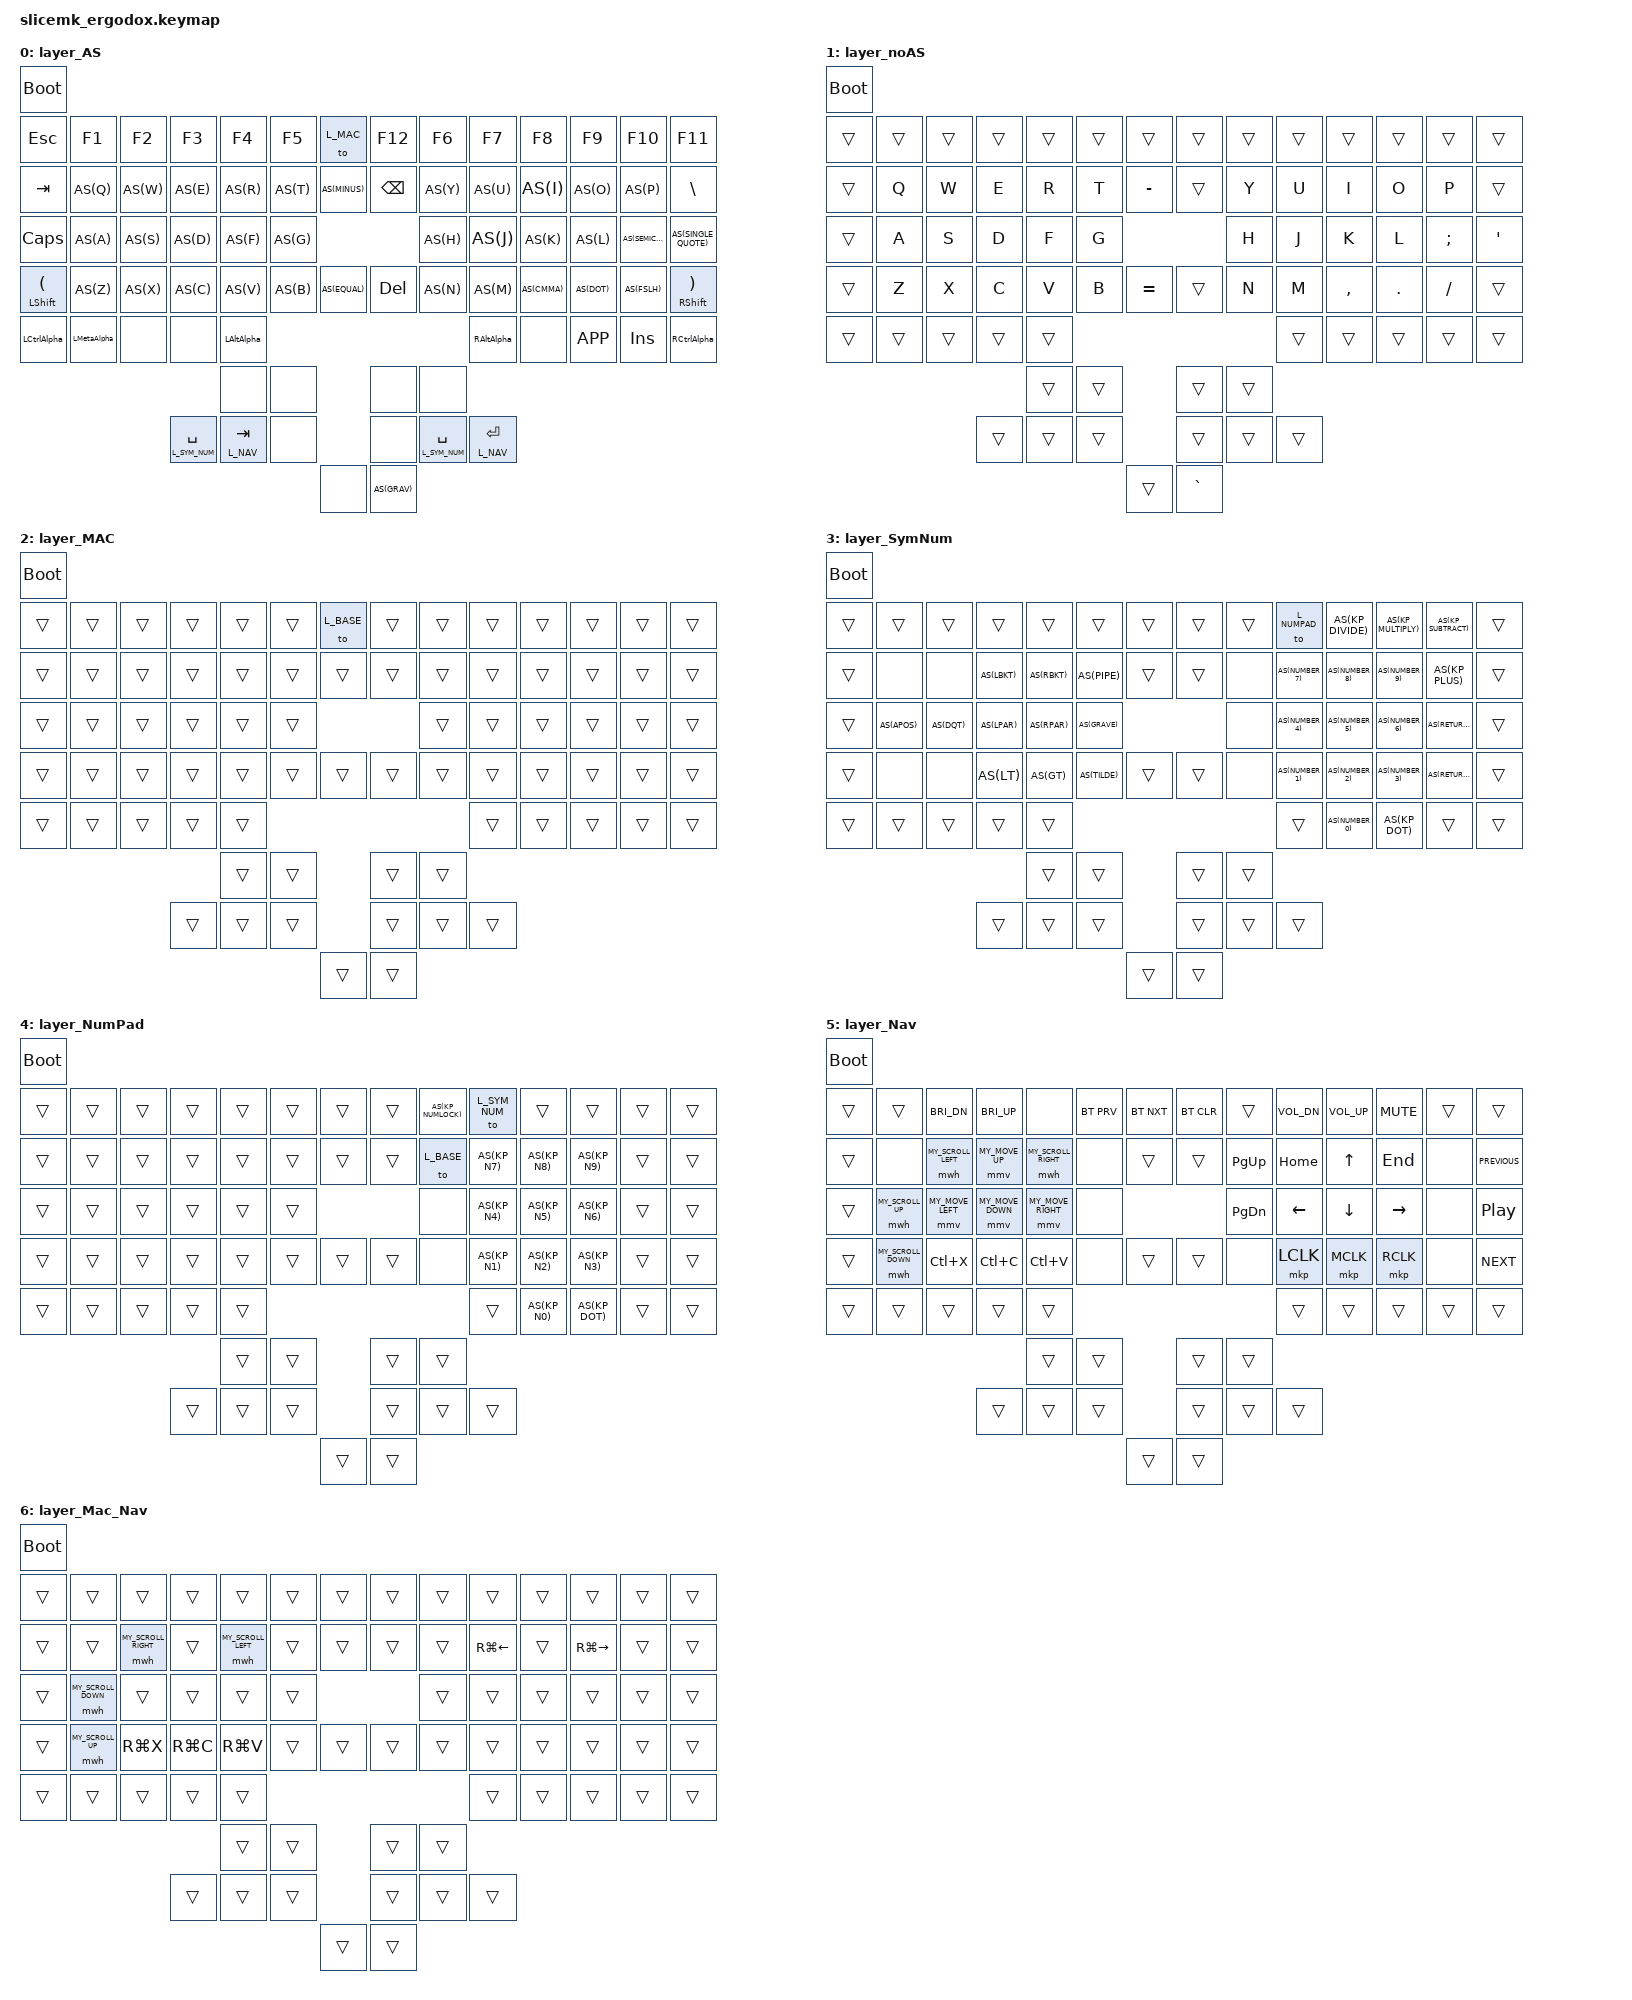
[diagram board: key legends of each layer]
#include <behaviors.dtsi>
#include <dt-bindings/zmk/bt.h>
#include <dt-bindings/zmk/keys.h>
#include <dt-bindings/zmk/outputs.h>
#include <dt-bindings/zmk/mouse.h>

// layers
#define L_BASE 0
#define L_NOAS 1
#define L_MAC 2
#define L_SYM_NUM 3
#define L_NUMPAD 4
#define L_NAV 5
#define L_MAC_NAV 6

// Mouse helpers
#define MY_MOUSE_SPEED 1400 // must be less than 16 bit signed (-32,768 to 32,767). Default 600
#define MY_MOVE_UP MOVE_VERT(-MY_MOUSE_SPEED)
#define MY_MOVE_DOWN MOVE_VERT(MY_MOUSE_SPEED)
#define MY_MOVE_LEFT MOVE_HOR(-MY_MOUSE_SPEED)
#define MY_MOVE_RIGHT MOVE_HOR(MY_MOUSE_SPEED)


#define MOUSE_LCLK &mkp LCLK
#define MOUSE_MCLK &mkp MCLK
#define MOUSE_RCLK &mkp RCLK
#define M_UP &mmv MY_MOVE_UP
#define M_DOWN &mmv MY_MOVE_DOWN
#define M_LEFT &mmv MY_MOVE_LEFT
#define M_RIGHT &mmv MY_MOVE_RIGHT

#define MY_SCROLL_SPEED 10 // must be less than 8 bit signed (	-128 to 127). Default 10
#define MY_SCROLL_UP SCROLL_VERT(MY_SCROLL_SPEED)
#define MY_SCROLL_DOWN SCROLL_VERT(-MY_SCROLL_SPEED)
#define MY_SCROLL_LEFT SCROLL_HOR(-MY_SCROLL_SPEED)
#define MY_SCROLL_RIGHT SCROLL_HOR(MY_SCROLL_SPEED)
#define M_WHEEL_L &mwh MY_SCROLL_LEFT
#define M_WHEEL_R &mwh MY_SCROLL_RIGHT
#define M_WHEEL_U &mwh MY_SCROLL_UP
#define M_WHEEL_D &mwh MY_SCROLL_DOWN

// Mouse movement settings
&mmv {
	delay-ms = <0>; // <0> default
	time-to-max-speed-ms = <300>; // <300> default
	acceleration-exponent = <1>; // <1> default
};

// Mouse Wheel settings
&mwh {
	delay-ms = <0>; // <0> default
	time-to-max-speed-ms = <0>; // <300> dafault
	acceleration-exponent = <0>; // <0> default
};

// Auto shift helper
#define AS(keycode) &as LS(keycode) keycode

// Windows helpers
#define W_CUT &kp LC(X)
#define W_COPY &kp LC(C)
#define W_PASTE &kp LC(V)

// Mac Helpers
#define M_LINE_START &kp RG(LEFT_ARROW)
#define M_LINE_END &kp RG(RIGHT_ARROW)
#define M_CUT &kp RG(X)
#define M_COPY &kp RG(C)
#define M_PASTE &kp RG(V)

/ { // root
	macros {
		LCtrlAlpha:LCtrlAlpha {
			compatible = "zmk,behavior-macro";
			label = "pressLeftCtrlNoAutoShiftMacro";
			#binding-cells = <0>;
			wait-ms = <0>;
			tap-ms = <0>;
			bindings
			= <&macro_press &mo L_NOAS &kp LCTRL>,
				<&macro_pause_for_release>,
				<&macro_release &mo L_NOAS &kp LCTRL> ;
		};
		LMetaAlpha:LMetaAlpha {
			compatible = "zmk,behavior-macro";
			label = "pressLeftMetaNoAutoShiftMacro";
			#binding-cells = <0>;
			wait-ms = <0>;
			tap-ms = <0>;
			bindings
			= <&macro_press &mo L_NOAS &kp LEFT_META>,
				<&macro_pause_for_release>,
				<&macro_release &mo L_NOAS &kp LEFT_META> ;
		};
		LAltAlpha:LAltAlpha {
			compatible = "zmk,behavior-macro";
			label = "pressLeftAltNoAutoShiftMacro";
			#binding-cells = <0>;
			wait-ms = <0>;
			tap-ms = <0>;
			bindings
			= <&macro_press &mo L_NOAS &kp LALT>,
				<&macro_pause_for_release>,
				<&macro_release &mo L_NOAS &kp LALT> ;
		};
		RCtrlAlpha:RCtrlAlpha {
			compatible = "zmk,behavior-macro";
			label = "pressRightCtrlNoAutoShiftMacro";
			#binding-cells = <0>;
			wait-ms = <0>;
			tap-ms = <0>;
			bindings
			= <&macro_press &mo L_NOAS &kp RCTRL>,
				<&macro_pause_for_release>,
				<&macro_release &mo L_NOAS &kp RCTRL> ;
		};
		RMetaAlpha:RMetaAlpha {
			compatible = "zmk,behavior-macro";
			label = "pressRightMetaNoAutoShiftMacro";
			#binding-cells = <0>;
			wait-ms = <0>;
			tap-ms = <0>;
			bindings
			= <&macro_press &mo L_NOAS &kp RIGHT_META>,
				<&macro_pause_for_release>,
				<&macro_release &mo L_NOAS &kp RIGHT_META> ;
		};
		RAltAlpha:RAltAlpha {
			compatible = "zmk,behavior-macro";
			label = "pressRightAltNoAutoShiftMacro";
			#binding-cells = <0>;
			wait-ms = <0>;
			tap-ms = <0>;
			bindings
			= <&macro_press &mo L_NOAS &kp RALT>,
				<&macro_pause_for_release>,
				<&macro_release &mo L_NOAS &kp RALT> ;
		};
	}; // macros

	behaviors {
		as: auto_shift {
			compatible = "zmk,behavior-hold-tap";
			label = "AUTO_SHIFT";
			#binding-cells = <2>;
			tapping_term_ms = <260>; // 300->slow, 190->fast
			quick_tap_ms = <0>;
			flavor = "tap-preferred";
			bindings = <&kp>, <&kp>;
		};
	}; // behaviors

	conditional_layers {
		compatible = "zmk,conditional-layers";
		tri_layer {
				if-layers = <L_MAC L_NAV>;
				then-layer = <L_MAC_NAV>;
		};
	}; // conditional_layers

	keymap {
		compatible = "zmk,keymap";
		layer_AS {  // L_BASE
			bindings = <
				&bootloader
				&kp ESC             &kp F1       &kp F2       &kp F3       &kp F4       &kp F5  &to L_MAC       &kp F12    &kp F6       &kp F7       &kp F8       &kp F9       &kp F10         &kp F11
				&kp TAB             AS(Q)        AS(W)        AS(E)        AS(R)        AS(T)   AS(MINUS)       &kp BKSP   AS(Y)        AS(U)        AS(I)        AS(O)        AS(P)           &kp BSLH
				&kp CAPS            AS(A)        AS(S)        AS(D)        AS(F)        AS(G)                              AS(H)        AS(J)        AS(K)        AS(L)        AS(SEMICOLON)   AS(SINGLE_QUOTE)
				&mt LSHIFT LPAR     AS(Z)        AS(X)        AS(C)        AS(V)        AS(B)   AS(EQUAL)       &kp DEL    AS(N)        AS(M)        AS(CMMA)     AS(DOT)      AS(FSLH)        &mt RSHIFT RPAR
				&LCtrlAlpha         &LMetaAlpha  &none        &none        &LAltAlpha                                                   &RAltAlpha   &none        &kp K_APP    &kp INS         &RCtrlAlpha
				                                                                 &none          &none           &none    &none
				                                            &lt L_SYM_NUM SPC    &lt L_NAV TAB  &none           &none    &lt L_SYM_NUM SPC    &lt L_NAV RET
				                                                                                &none           AS(GRAV)
			>; // bindings
		}; // layer

		layer_noAS {  // L_XYZ
			bindings = <
				&bootloader
				&trans  &trans  &trans  &trans  &trans  &trans  &trans       &trans  &trans  &trans  &trans   &trans  &trans        &trans
				&trans  &kp Q   &kp W   &kp E   &kp R   &kp T   &kp MINUS    &trans  &kp Y   &kp U   &kp I    &kp O   &kp P         &trans
				&trans  &kp A   &kp S   &kp D   &kp F   &kp G                        &kp H   &kp J   &kp K    &kp L   &kp SEMICOLON &kp SINGLE_QUOTE
				&trans  &kp Z   &kp X   &kp C   &kp V   &kp B   &kp EQUAL    &trans  &kp N   &kp M   &kp CMMA &kp DOT &kp FSLH      &trans
				&trans  &trans  &trans  &trans  &trans                                       &trans  &trans   &trans  &trans        &trans
				                                        &trans  &trans       &trans  &trans
				                                &trans  &trans  &trans       &trans  &trans  &trans
				                                                &trans       &kp GRAV
			>; // bindings
		}; // layer

		layer_MAC {  // L_MAC
			bindings = <
				&bootloader
				&trans  &trans  &trans  &trans  &trans  &trans  &to L_BASE   &trans  &trans  &trans  &trans  &trans  &trans  &trans
				&trans  &trans  &trans  &trans  &trans  &trans  &trans       &trans  &trans  &trans  &trans  &trans  &trans  &trans
				&trans  &trans  &trans  &trans  &trans  &trans                       &trans  &trans  &trans  &trans  &trans  &trans
				&trans  &trans  &trans  &trans  &trans  &trans  &trans       &trans  &trans  &trans  &trans  &trans  &trans  &trans
				&trans  &trans  &trans  &trans  &trans                                       &trans  &trans  &trans  &trans  &trans
				                                       &trans  &trans        &trans  &trans
				                               &trans  &trans  &trans        &trans  &trans  &trans
				                                               &trans        &trans
			>; // bindings
		}; // layer



		layer_SymNum { // L_SYM_NUM
			bindings = <
				&bootloader
				&trans   &trans       &trans       &trans       &trans     &trans    &trans     &trans &trans &to L_NUMPAD AS(KP_DIVIDE)  AS(KP_MULTIPLY)  AS(KP_SUBTRACT)  &trans
				&trans   &none        &none        AS(LBKT)     AS(RBKT)   AS(PIPE)  &trans     &trans &none  AS(NUMBER_7) AS(NUMBER_8)   AS(NUMBER_9)     AS(KP_PLUS)      &trans
				&trans   AS(APOS)     AS(DQT)      AS(LPAR)     AS(RPAR)   AS(GRAVE)                   &none  AS(NUMBER_4) AS(NUMBER_5)   AS(NUMBER_6)     AS(RETURN2)      &trans
				&trans   &none        &none        AS(LT)       AS(GT)     AS(TILDE) &trans     &trans &none  AS(NUMBER_1) AS(NUMBER_2)   AS(NUMBER_3)     AS(RETURN2)      &trans
				&trans   &trans       &trans       &trans       &trans                                        &trans       AS(NUMBER_0)   AS(KP_DOT)       &trans           &trans
				                                                               &trans &trans   &trans  &trans
				                                                       &trans  &trans &trans   &trans  &trans &trans
				                                                                      &trans   &trans
			>; // bindings
		}; // layer

		layer_NumPad {  // L_NUMPAD
			bindings = <
				&bootloader
				&trans   &trans       &trans       &trans       &trans     &trans    &trans     &trans AS(KP_NUMLOCK)  &to L_SYM_NUM  &trans          &trans           &trans      &trans
				&trans   &trans       &trans       &trans       &trans     &trans    &trans     &trans &to L_BASE      AS(KP_N7)      AS(KP_N8)       AS(KP_N9)         &trans      &trans
				&trans   &trans       &trans       &trans       &trans     &trans                      &none           AS(KP_N4)      AS(KP_N5)       AS(KP_N6)         &trans      &trans
				&trans   &trans       &trans       &trans       &trans     &trans    &trans     &trans &none           AS(KP_N1)      AS(KP_N2)       AS(KP_N3)         &trans      &trans
				&trans   &trans       &trans       &trans       &trans                                                 &trans         AS(KP_N0)       AS(KP_DOT)        &trans      &trans
				                                                               &trans &trans   &trans  &trans
				                                                       &trans  &trans &trans   &trans  &trans &trans
				                                                                      &trans   &trans
			>; // bindings
		}; // layer

		layer_Nav { // L_NAV
			bindings = <
				&bootloader
				&trans &trans     &kp C_BRI_DN  &kp C_BRI_UP  &none          &bt BT_PRV &bt BT_NXT      &bt BT_CLR  &trans        &kp C_VOL_DN   &kp C_VOL_UP   &kp C_MUTE      &trans       &trans
				&trans &none      M_WHEEL_L     M_UP          M_WHEEL_R      &none      &trans          &trans      &kp PAGE_UP   &kp HOME       &kp UP_ARROW   &kp END         &none        &kp C_PREVIOUS
				&trans M_WHEEL_U  M_LEFT        M_DOWN        M_RIGHT        &none                                  &kp PAGE_DOWN &kp LEFT_ARROW &kp DOWN_ARROW &kp RIGHT_ARROW &none        &kp C_PLAY_PAUSE
				&trans M_WHEEL_D  W_CUT         W_COPY        W_PASTE        &none      &trans          &trans      &none         MOUSE_LCLK     MOUSE_MCLK     MOUSE_RCLK      &none        &kp C_NEXT
				&trans &trans     &trans        &trans        &trans                                                              &trans         &trans         &trans          &trans       &trans
				                                                                &trans &trans           &trans      &trans
				                                                       &trans   &trans &trans           &trans      &trans   &trans
				                                                                       &trans           &trans
			>; // bindings
		}; // layer

		layer_Mac_Nav { // L_MAC_NAV
			bindings = <
				&bootloader
				&trans  &trans     &trans      &trans  &trans     &trans  &trans       &trans  &trans  &trans       &trans  &trans      &trans  &trans
				&trans  &trans     M_WHEEL_R   &trans  M_WHEEL_L  &trans  &trans       &trans  &trans  M_LINE_START &trans  M_LINE_END  &trans  &trans
				&trans  M_WHEEL_D  &trans      &trans  &trans     &trans                       &trans  &trans       &trans  &trans      &trans  &trans
				&trans  M_WHEEL_U  M_CUT       M_COPY  M_PASTE     &trans  &trans       &trans  &trans  &trans       &trans  &trans      &trans  &trans
				&trans  &trans     &trans      &trans  &trans                                       &trans          &trans  &trans      &trans  &trans
				                                        &trans  &trans       &trans  &trans
				                                &trans  &trans  &trans       &trans  &trans  &trans
				                                                &trans       &trans
			>; // bindings
		}; // layer

		/* transparent starter
		layer_1 {  // L_XYZ
			bindings = <
				&bootloader
				&trans  &trans  &trans  &trans  &trans  &trans  &trans       &trans  &trans  &trans  &trans  &trans  &trans  &trans
				&trans  &trans  &trans  &trans  &trans  &trans  &trans       &trans  &trans  &trans  &trans  &trans  &trans  &trans
				&trans  &trans  &trans  &trans  &trans  &trans                       &trans  &trans  &trans  &trans  &trans  &trans
				&trans  &trans  &trans  &trans  &trans  &trans  &trans       &trans  &trans  &trans  &trans  &trans  &trans  &trans
				&trans  &trans  &trans  &trans  &trans                                       &trans  &trans  &trans  &trans  &trans
				                                        &trans  &trans       &trans  &trans
				                                &trans  &trans  &trans       &trans  &trans  &trans
				                                                &trans       &trans
			>; // bindings
		}; // layer
		*/

		/* blank starter
		layer_1 {  // L_XYZ
			bindings = <
				&bootloader
				&none  &none  &none  &none  &none  &none  &none       &none  &none  &none  &none  &none  &none  &none
				&none  &none  &none  &none  &none  &none  &none       &none  &none  &none  &none  &none  &none  &none
				&none  &none  &none  &none  &none  &none                     &none  &none  &none  &none  &none  &none
				&none  &none  &none  &none  &none  &none  &none       &none  &none  &none  &none  &none  &none  &none
				&none  &none  &none  &none  &none                                   &none  &none  &none  &none  &none
				                                   &none  &none       &none  &none
				                            &none  &none  &none       &none  &none  &none
				                                          &none       &none
			>; // bindings
		}; // layer
		*/
	}; // keymap
}; // root
